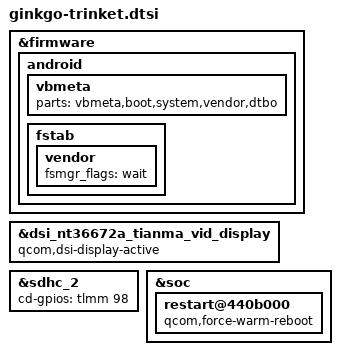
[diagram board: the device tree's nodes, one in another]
#include "../qcom-base/trinket-idp.dtsi"
#include "../qcom-base/ginkgo-touchpad.dtsi"
#include "../qcom-base/trinket-audio-overlay.dtsi"

&firmware {
	android {
		vbmeta {
			parts = "vbmeta,boot,system,vendor,dtbo";
		};

		fstab {
			vendor {
				fsmgr_flags = "wait";
			};
		};
	};
};

&dsi_nt36672a_tianma_vid_display {
	qcom,dsi-display-active;
};

&sdhc_2 {
	cd-gpios = <&tlmm 98 0>;
};

&soc {
    restart@440b000 {
        qcom,force-warm-reboot;
    };
};
